# AS32x601 register map
File version: 1.0
CPU: RISC-V, little endian
Registers are 32-bit, read-write, reset 0x0 unless marked. A register's access mark holds for its fields unless they carry their own. Offsets are from the block's base; [hi:lo] are bit positions; {n}, {i} and the like mark numbered series.

## HTIM0 — Advanced Timer 0
Base 0x41000000
Same registers: HTIM1 0x42000000, HTIM2 0x5000A000, HTIM5 0x51009000
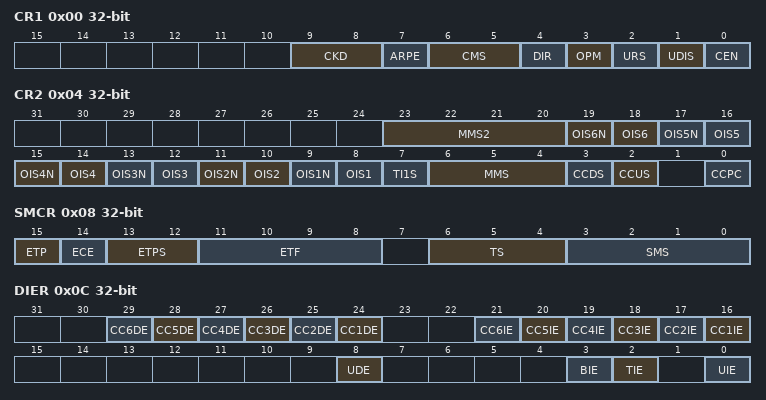
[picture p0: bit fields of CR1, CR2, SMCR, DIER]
0x00 CR1 — TIMx control register 1
  [9:8] CKD — Clock division
  [7] ARPE — Auto-reload preload enable
  [6:5] CMS — Center-aligned mode selection
  [4] DIR — Direction
  [3] OPM — One pulse mode
  [2] URS — Update request source
  [1] UDIS — Update disable
  [0] CEN — Counter enable
0x04 CR2 — TIMx control register 2
  [23:20] MMS2 — Master mode selection 2
  [2n+7] OIS{n}N (n=1..6) — Output Idle state {n} (OC{n}N output)
  [2n+6] OIS{n} (n=1..6) — Output Idle state {n} (OC{n} output)
  [7] TI1S — TI1 selection
  [6:4] MMS — Master mode selection
  [3] CCDS — Capture/compare DMA selection
  [2] CCUS — Capture/compare control update selection
  [0] CCPC — Capture/compare preloaded control
0x08 SMCR — TIMx slave mode control register
  [15] ETP — External trigger polarity
  [14] ECE — External clock enable
  [13:12] ETPS — External trigger prescaler
  [11:8] ETF — External trigger filter
  [6:4] TS — Trigger selection
  [3:0] SMS — Slave mode selection
0x0C DIER — TIMx DMA/interrupt enable register
  [n+23] CC{n}DE (n=1..6) — Capture/Compare {n} DMA request enable
  [n+15] CC{n}IE (n=1..6) — Capture/Compare {n} interrupt enable
  [8] UDE — Update DMA request enable
  [3] BIE — Break interrupt enable
  [2] TIE — Trigger interrupt enable
  [0] UIE — Update interrupt enable
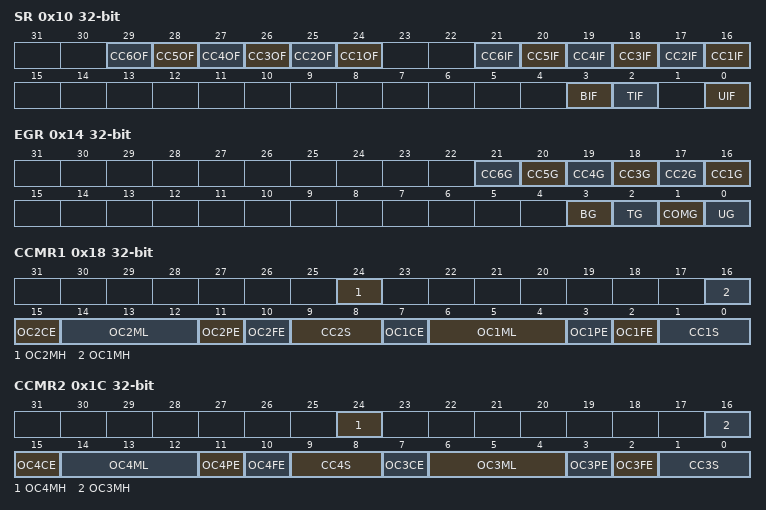
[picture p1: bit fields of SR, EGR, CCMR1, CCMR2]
0x10 SR — TIMx status register
  [n+23] CC{n}OF (n=1..6) — Capture/Compare {n} overcapture flag
  [n+15] CC{n}IF (n=1..6) — Capture/Compare {n} interrupt flag
  [3] BIF — Break interrupt flag
  [2] TIF — Trigger interrupt flag
  [0] UIF — Update interrupt flag
0x14 EGR — TIMx event generation register
  [n+15] CC{n}G (n=1..6) — Capture/Compare {n} generation
  [3] BG — Break generation
  [2] TG — Trigger generation
  [1] COMG — Capture/Compare control update generation
  [0] UG — Update generation
0x18 CCMR1 — TIMx capture/compare mode register 1
  [24] OC2MH — Output Compare 2 mode
  [16] OC1MH — Output Compare 1 mode
  [15] OC2CE — Output Compare 2 clear enable
  [14:12] OC2ML — Output Compare 2 mode
  [11] OC2PE — Output Compare 2 preload enable
  [10] OC2FE — Output Compare 2 fast enable
  [9:8] CC2S — Capture/Compare 2 selection
  [7] OC1CE — Output Compare 1 clear enable
  [6:4] OC1ML — Output Compare 1 mode
  [3] OC1PE — Output Compare 1 preload enable
  [2] OC1FE — Output Compare 1 fast enable
  [1:0] CC1S — Capture/Compare 1 selection
0x1C CCMR2 — TIMx capture/compare mode register 2
  [24] OC4MH — Output compare 4 mode
  [16] OC3MH — Output compare 3 mode
  [15] OC4CE — Output compare 4 clear enable
  [14:12] OC4ML — Output compare 4 mode
  [11] OC4PE — Output compare 4 preload enable
  [10] OC4FE — Output compare 4 fast enable
  [9:8] CC4S — Capture/Compare 4 selection
  [7] OC3CE — Output compare 3 clear enable
  [6:4] OC3ML — Output compare 3 mode
  [3] OC3PE — Output compare 3 preload enable
  [2] OC3FE — Output compare 3 fast enable
  [1:0] CC3S — Capture/Compare 3 selection
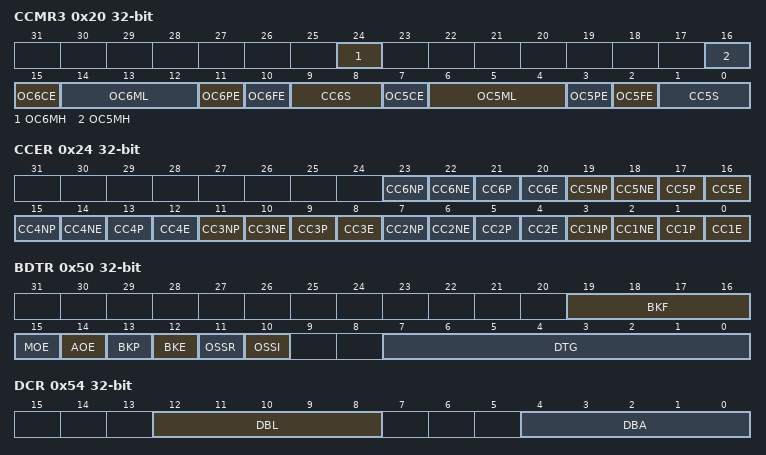
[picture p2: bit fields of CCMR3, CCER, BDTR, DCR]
0x20 CCMR3 — TIMx capture/compare mode register 3
  [24] OC6MH — Output compare 6 mode
  [16] OC5MH — Output compare 5 mode
  [15] OC6CE — Output compare 6 clear enable
  [14:12] OC6ML — Output compare 6 mode
  [11] OC6PE — Output compare 6 preload enable
  [10] OC6FE — Output compare 6 fast enable
  [9:8] CC6S — Capture/Compare 6 selection
  [7] OC5CE — Output compare 5 clear enable
  [6:4] OC5ML — Output compare 5 mode
  [3] OC5PE — Output compare 5 preload enable
  [2] OC5FE — Output compare 5 fast enable
  [1:0] CC5S — Capture/Compare 5 selection
0x24 CCER — TIMx capture/compare enable register
  [4n-1] CC{n}NP (n=1..6) — Capture/Compare {n} complementary output polarity
  [4n-2] CC{n}NE (n=1..6) — Capture/Compare {n} complementary output enable
  [4n-3] CC{n}P (n=1..6) — Capture/Compare {n} output polarity
  [4n-4] CC{n}E (n=1..6) — Capture/Compare {n} output enable
0x28 CNT ro — TIMx counter
  [31:0] CNT — Counter value
0x2C PSC — TIMx prescaler
  [31:0] PSC — Prescaler value
0x30 ARR reset 0xFFFFFFFF — TIMx auto-reload register
  [31:0] ARR — Auto-reload value
0x34 RCR — TIMx repetition counter register
  [15:0] REP — Repetition counter value
{0x34+4i} CCR{i} (i=1..6) — TIMx capture/compare register {i}
  [31:0] CCR{i} — Capture/Compare {i} value
0x50 BDTR — TIMx break and dead-time register
  [19:16] BKF — Break filter
  [15] MOE — Main output enable
  [14] AOE — Automatic output enable
  [13] BKP — Break polarity
  [12] BKE — Break enable
  [11] OSSR — Off-state selection for Run mode
  [10] OSSI — Off-state selection for Idle mode
  [7:0] DTG — Dead-time generator setup
0x54 DCR — TIMx DMA control register
  [12:8] DBL — DMA burst length
  [4:0] DBA — DMA base address
0x58 DMAR — TIMx DMA address for full transfer
  [31:0] DMAB — DMA register for burst accesses
0x5C AF1 — TIMx alternate function option register 1
  [3:0] ETRSEL — ETR source selection

## TIM3 — General Purpose Timer 3
Base 0x5000B000
Same registers: TIM4 0x5000C000, TIM6 0x5100A000, TIM7 0x5100B000
Registers as HTIM0, without CCMR3, RCR, CCR5, CCR6, BDTR, AF1; these are added or differ:
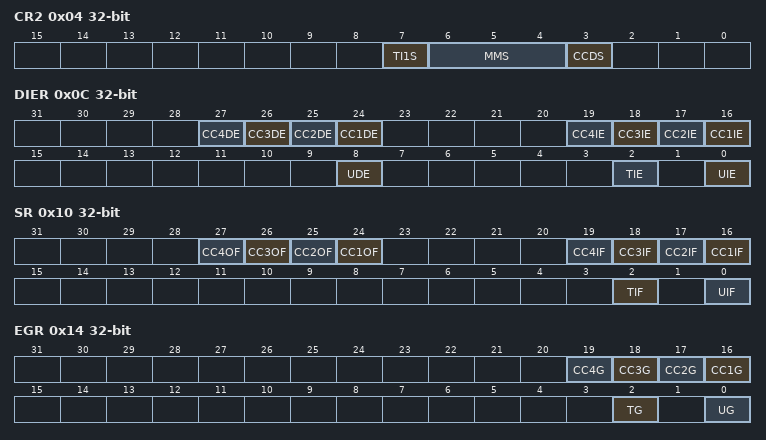
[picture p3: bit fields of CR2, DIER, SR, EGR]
0x04 CR2 — TIMx control register 2
  [7] TI1S — TI1 selection
  [6:4] MMS — Master mode selection
  [3] CCDS — Capture/compare DMA selection
0x0C DIER — TIMx DMA/interrupt enable register
  [n+23] CC{n}DE (n=1..4) — Capture/Compare {n} DMA request enable
  [n+15] CC{n}IE (n=1..4) — Capture/Compare {n} interrupt enable
  [8] UDE — Update DMA request enable
  [2] TIE — Trigger interrupt enable
  [0] UIE — Update interrupt enable
0x10 SR — TIMx status register
  [n+23] CC{n}OF (n=1..4) — Capture/Compare {n} overcapture flag
  [n+15] CC{n}IF (n=1..4) — Capture/Compare {n} interrupt flag
  [2] TIF — Trigger interrupt flag
  [0] UIF — Update interrupt flag
0x14 EGR — TIMx event generation register
  [n+15] CC{n}G (n=1..4) — Capture/Compare {n} generation
  [2] TG — Trigger generation
  [0] UG — Update generation
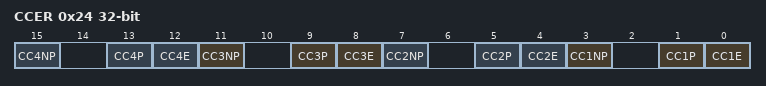
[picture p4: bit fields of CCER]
0x24 CCER — TIMx capture/compare enable register
  [4n-1] CC{n}NP (n=1..4) — Capture/Compare {n} complementary output polarity
  [4n-3] CC{n}P (n=1..4) — Capture/Compare {n} output polarity
  [4n-4] CC{n}E (n=1..4) — Capture/Compare {n} output enable
0x28 CNT ro — TIMx counter
  [15:0] CNT — Counter value
0x2C PSC — TIMx prescaler
  [15:0] PSC — Prescaler value
0x30 ARR reset 0xFFFF — TIMx auto-reload register
  [15:0] ARR — Auto-reload value
{0x34+4i} CCR{i} (i=1..4) — TIMx capture/compare register {i}
  [15:0] CCR{i} — Capture/Compare {i} value
